# PIC32CX1025SG60100 device description
Architecture: CORTEX-M4; Family: PIC32CX; Series: PIC32CXSG60
Registers are 32-bit, read-write, reset 0x0 unless marked. A register's access mark holds for its fields unless they carry their own. Offsets are from the block's base; [hi:lo] are bit positions; {n}, {i} and the like mark numbered series.

## NVIC — Nested Vectored Interrupt Controller
Instances: NVIC 0xE000E100
{0x0+4i} ISER[{i}] (i=0..4) — Interrupt Set Enable Register
  [31:0] SETENA — Interrupt set enable bits
{0x80+4i} ICER[{i}] (i=0..4) — Interrupt Clear Enable Register
  [31:0] CLRENA — Interrupt clear-enable bits
{0x100+4i} ISPR[{i}] (i=0..4) — Interrupt Set Pending Register
  [31:0] SETPEND — Interrupt set-pending bits
{0x180+4i} ICPR[{i}] (i=0..4) — Interrupt Clear Pending Register
  [31:0] CLRPEND — Interrupt clear-pending bits
{0x200+4i} IABR[{i}] (i=0..4) — Interrupt Active Bit Register
  [31:0] ACTIVE — Interrupt active bits
{0x300+i} IP[{i}] (i=0..34) 8-bit — Interrupt Priority Register n
  [2:0] PRI0 — Priority of interrupt n
0xE00 STIR wo reset not defined — Software Trigger Interrupt Register
  [8:0] INTID — Interrupt ID to trigger

## SysTick — System timer
Instances: SysTick 0xE000E010
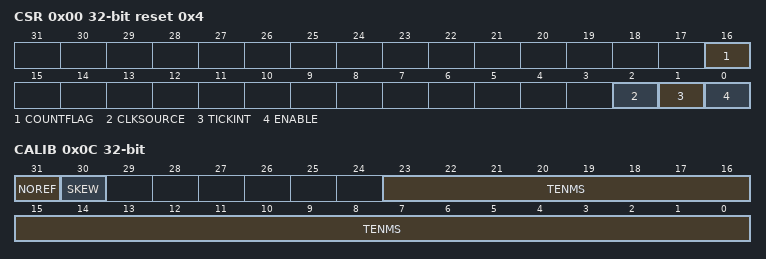
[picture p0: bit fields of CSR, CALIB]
0x00 CSR reset 0x4 — SysTick Control and Status Register
  [16] COUNTFLAG — Timer counted to 0 since last read of register
  [2] CLKSOURCE — Clock Source 0=external, 1=processor
    0=External clock; 1=Processor clock
  [1] TICKINT — SysTick Exception Request Enable
    0=Counting down to 0 does not assert the SysTick exception request; 1=Counting down to 0 asserts the SysTick exception request
  [0] ENABLE — SysTick Counter Enable
    0=Counter disabled; 1=Counter enabled
0x04 RVR reset not defined — SysTick Reload Value Register
  [23:0] RELOAD — Value to load into the SysTick Current Value Register when the counter reaches 0
0x08 CVR reset not defined — SysTick Current Value Register
  [23:0] CURRENT — Current value at the time the register is accessed
0x0C CALIB ro — SysTick Calibration Value Register
  [31] NOREF — No Separate Reference Clock
    0=The reference clock is provided; 1=The reference clock is not provided
  [30] SKEW — TENMS is rounded from non-integer ratio
    0=10ms calibration value is exact; 1=10ms calibration value is inexact, because of the clock frequency
  [23:0] TENMS — Reload value to use for 10ms timing

## TPIU — Trace Port Interface Register
Instances: TPIU 0xE0040000
0x00 SSPSR ro reset not defined — Supported Parallel Port Size Register
0x04 CSPSR reset not defined — Current Parallel Port Size Register
0x10 ACPR reset not defined — Asynchronous Clock Prescaler Register
  [12:0] PRESCALER
0xF0 SPPR reset not defined — Selected Pin Protocol Register
  [1:0] TXMODE
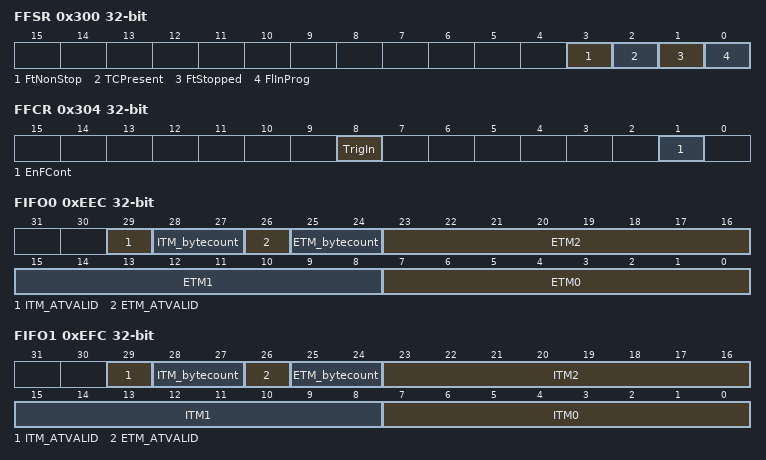
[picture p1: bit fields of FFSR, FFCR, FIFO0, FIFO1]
0x300 FFSR ro reset not defined — Formatter and Flush Status Register
  [3] FtNonStop, [2] TCPresent, [1] FtStopped, [0] FlInProg
0x304 FFCR reset not defined — Formatter and Flush Control Register
  [8] TrigIn, [1] EnFCont
0x308 FSCR ro reset not defined — Formatter Synchronization Counter Register
0xEE8 TRIGGER ro reset not defined
  [0] TRIGGER
0xEEC FIFO0 ro reset not defined — Integration ETM Data
  [29] ITM_ATVALID, [28:27] ITM_bytecount, [26] ETM_ATVALID, [25:24] ETM_bytecount, [23:16] ETM2, [15:8] ETM1, [7:0] ETM0
0xEF0 ITATBCTR2 ro reset not defined
  [0] ATREADY
0xEF8 ITATBCTR0 ro reset not defined
  [0] ATREADY
0xEFC FIFO1 ro reset not defined — Integration ITM Data
  [29] ITM_ATVALID, [28:27] ITM_bytecount, [26] ETM_ATVALID, [25:24] ETM_bytecount, [23:16] ITM2, [15:8] ITM1, [7:0] ITM0
0xF00 ITCTRL reset not defined — Integration Mode Control
  [0] Mode
0xFA0 CLAIMSET reset not defined (atomic set) — Claim tag set
0xFA4 CLAIMCLR reset not defined (atomic clear) — Claim tag clear
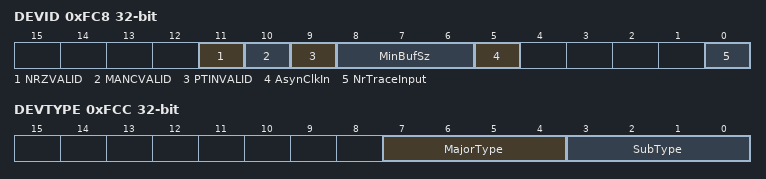
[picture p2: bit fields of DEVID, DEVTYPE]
0xFC8 DEVID ro reset not defined — TPIU_DEVID
  [11] NRZVALID, [10] MANCVALID, [9] PTINVALID, [8:6] MinBufSz, [5] AsynClkIn, [0] NrTraceInput
0xFCC DEVTYPE ro reset not defined — TPIU_DEVTYPE
  [7:4] MajorType, [3:0] SubType

## Notices in the file
Copyright (c) 2021 Microchip Technology Inc.
SPDX-License-Identifier: Apache-2.0
Licensed under the Apache License, Version 2.0 (the "License");
you may not use this file except in compliance with the License.
You may obtain a copy of the License at
http://www.apache.org/licenses/LICENSE-2.0
Unless required by applicable law or agreed to in writing, software
distributed under the License is distributed on an "AS IS" BASIS,
WITHOUT WARRANTIES OR CONDITIONS OF ANY KIND, either express or implied.
See the License for the specific language governing permissions and
limitations under the License.
